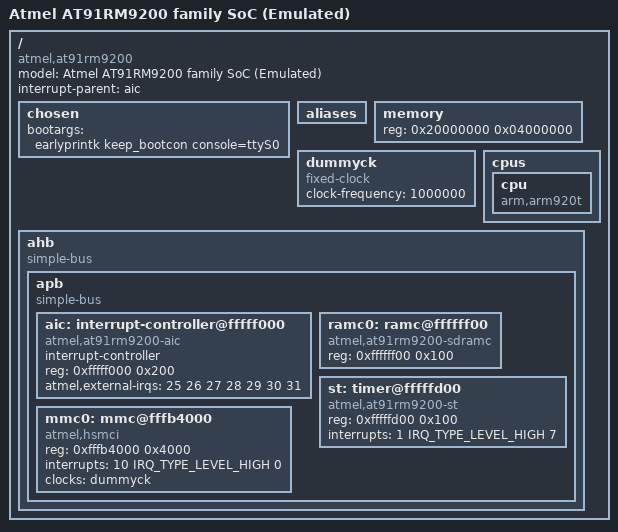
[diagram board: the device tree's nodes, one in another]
/dts-v1/;

#include <dt-bindings/interrupt-controller/irq.h>

/* skeleton */
/ {
	#address-cells = <1>;
	#size-cells = <1>;
	chosen { };
	aliases { };
	memory { device_type = "memory"; reg = <0 0>; };
};

/* at91rm9200 */
/ {
	model = "Atmel AT91RM9200 family SoC (Emulated)";
	compatible = "atmel,at91rm9200";
	interrupt-parent = <&aic>;

	dummyck: dummyck {
		compatible = "fixed-clock";
		clock-frequency = <1000000>;
		#clock-cells = <0>;
	};

	cpus {
		#address-cells = <0>;
		#size-cells = <0>;
		cpu {
			compatible = "arm,arm920t";
			device_type = "cpu";
		};
	};

	ahb {
		compatible = "simple-bus";
		#address-cells = <1>;
		#size-cells = <1>;
		ranges;
		apb {
			compatible = "simple-bus";
			#address-cells = <1>;
			#size-cells = <1>;
			ranges;
			aic: interrupt-controller@fffff000 {
				#interrupt-cells = <3>;
				compatible = "atmel,at91rm9200-aic";
				interrupt-controller;
				reg = <0xfffff000 0x200>;
				atmel,external-irqs = <25 26 27 28 29 30 31>;
			};
			ramc0: ramc@ffffff00 {
				compatible = "atmel,at91rm9200-sdramc";
				reg = <0xffffff00 0x100>;
			};
			st: timer@fffffd00 {
				compatible = "atmel,at91rm9200-st";
				reg = <0xfffffd00 0x100>;
				interrupts = <1 IRQ_TYPE_LEVEL_HIGH 7>;
			};
			mmc0: mmc@fffb4000 {
				compatible = "atmel,hsmci";
				reg = <0xfffb4000 0x4000>;
				interrupts = <10 IRQ_TYPE_LEVEL_HIGH 0>;
				clock-names = "mci_clk";
				clocks = <&dummyck>;
			};
		};
	};
};

/* emulator */
/ {
	memory {
		reg = <0x20000000 0x04000000>; /* 64 MiB */
	};
};

/* overridden */
/ {
	chosen {
		bootargs = "earlyprintk keep_bootcon console=ttyS0";
	};
};
